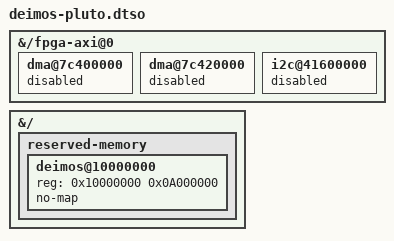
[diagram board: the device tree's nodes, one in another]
// packaging/deimos-pluto.dtso — Device tree overlay for Deimos on PlutoSDR
//
// Applied at packaging time via fdtoverlay to stock PlutoSDR DTBs.
// Same pattern as styx's styx-pluto.dtso — same memory layout
// (160 MB at 0x10000000), same ADI DMA disable.
//
// Changes:
//   1. Disable ADI HDL DMA engines (replaced by styx iq_dma_rx/tx)
//   2. Disable the PL I2C node: styx has no axi_iic core. A probe of the
//      missing core would hit an unmapped address.
//   3. Reserve 160 MB DDR for IQ DMA buffers (128 MB RX + 32 MB TX)
//
// The Rev.C DTB also has a PL SPI node (spi@7C430000). The other DTBs do
// not, and an overlay cannot target a node that may be missing. So
// package.sh disables that node with fdtput instead.

/dts-v1/;
/plugin/;

&{/fpga-axi@0} {
	dma@7c400000 {
		status = "disabled";
	};
	dma@7c420000 {
		status = "disabled";
	};
	// PL I2C (ADM1177 power monitor) — core removed from the styx BD
	i2c@41600000 {
		status = "disabled";
	};
};

&{/} {
	reserved-memory {
		#address-cells = <0x01>;
		#size-cells = <0x01>;
		ranges;

		deimos@10000000 {
			reg = <0x10000000 0x0A000000>;
			no-map;
		};
	};
};
